# spi1_secure register map
Vendor: Texas Instruments
Peripheral module from a debugger description file (folder CC35X1E).
Registers are 32-bit, access per field, reset 0x0 unless marked. A register's access mark holds for its fields unless they carry their own. Offsets are as the file gives them; lines under a group give offsets from that group; [hi:lo] are bit positions; {n}, {i} and the like mark numbered series; 'fields as' and 'values as' point back to an identical list; <NAME> marks a mode.

## spi1_secure
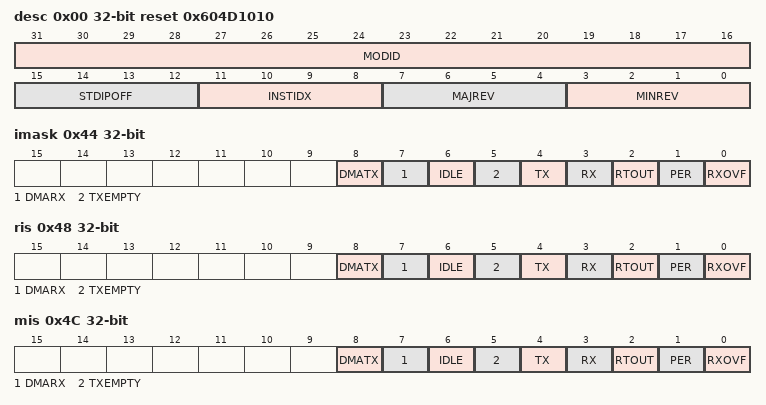
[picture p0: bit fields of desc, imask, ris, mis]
0x00 desc ro reset 0x604D1010 — Description Register. This register provides IP module ID, revision information, instance index and standard MMR registers offset.
  [31:16] MODID — Module identifier used to uniquely identify this IP.
  [15:12] STDIPOFF — Standard IP MMR block offset. Standard IP MMRs are the set of from aggregated IRQ registers till DTB. 0: Standard IP MMRs do not exist 0x1-0xF: Standard IP MMRs begin at offset of (64*[STDIPOFF] from the base IP address)
  [11:8] INSTIDX — IP Instance ID number. If multiple instances of IP exist in the device, this field can identify the instance number (0-15).
  [7:4] MAJREV — Major revision of IP (0-15).
  [3:0] MINREV — Minor revision of IP (0-15).
0x44 imask — Interrupt mask. This register selects interrupt sources which are allowed to pass from [RIS.*] to [MIS.*] when the corresponding bit-fields are set to 1.
  [8] DMATX rw — DMA Done TX event mask.
    1=SET (Set Interrrupt Mask); 0=CLR (Clear Interrupt Mask)
  [7] DMARX rw — DMA Done RX event mask.
    1=SET (Set Interrrupt Mask); 0=CLR (Clear Interrupt Mask)
  [6] IDLE rw — SPI Idle event mask.
    1=SET (Set Interrrupt Mask); 0=CLR (Clear Interrupt Mask)
  [5] TXEMPTY rw — Transmit FIFO Empty event mask.
    1=SET (Set Interrrupt Mask); 0=CLR (Clear Interrupt Mask)
  [4] TX rw — Transmit FIFO event mask.
    1=SET (Set Interrrupt Mask); 0=CLR (Clear Interrupt Mask)
  [3] RX rw — Receive FIFO event.
    1=SET (Set Interrupt Mask); 0=CLR (Clear Interrupt Mask)
  [2] RTOUT rw — SPI Receive Time-Out event mask.
    1=SET (Set Interrrupt Mask); 0=CLR (Clear Interrupt Mask)
  [1] PER rw — Parity error event mask.
    1=SET (Set Interrrupt Mask); 0=CLR (Clear Interrupt Mask)
  [0] RXOVF rw — RXFIFO overflow event mask.
    1=SET (Set Interrrupt Mask); 0=CLR (Clear Interrupt Mask)
0x48 ris ro — Raw interrupt status. This register reflects the state of all pending interrupts, regardless of masking. This register allows the user to implement a poll scheme. A flag set in this register can be cleared by writing 1 to the corresponding [ICLR.*] register bit.
  [all] fields
    1=SET (Interrupt occurred); 0=CLR (Interrupt did not occur)
  [8] DMATX — DMA Done event for TX. This interrupt is set if the TX DMA channel sends the DONE signal. This allows the handling of the TX DMA event inside SPI.
  [7] DMARX — DMA Done event for RX. This interrupt is set if the RX DMA channel sends the DONE signal. This allows handling of the DMA RX event inside SPI.
  [6] IDLE — SPI has completed transfers and moved to IDLE mode. This bit is set when [STA.BUSY] goes low.
  [5] TXEMPTY — Transmit FIFO Empty interrupt mask. This interrupt is set when all data in the Transmit FIFO has been moved to the shift register.
  [4] TX — Transmit FIFO event.This interrupt is set if the selected Transmit FIFO level has been reached.
  [3] RX — Receive FIFO event.This interrupt is set if the selected Receive FIFO level has been reached
  [2] RTOUT — SPI Receive Time-Out event. This interrupt is set if no activity is detected on the input clock line within the time period dictated by [CTL1.RTOUT] value. This is applicable only in peripheral mode.
  [1] PER — Parity error event. This bit is set if a Parity error has been detected
  [0] RXOVF — RXFIFO overflow event. This interrupt is set if an RX FIFO overflow has been detected.
0x4C mis ro — Masked interrupt status. This register is simply a bitwise AND of the contents of [IMASK.*] and [RIS.*] registers. A flag set in this register can be cleared by writing 1 to the corresponding [ICLR.*] register bit.
  [all] fields
    1=SET (Interrupt occurred); 0=CLR (Interrupt did not occur)
  [8] DMATX — Masked DMA Done event for TX.
  [7] DMARX — Masked DMA Done event for RX.
  [6] IDLE — Masked SPI IDLE event.
  [5] TXEMPTY — Masked Transmit FIFO Empty event.
  [4] TX — Masked Transmit FIFO event.
  [3] RX — Masked receive FIFO event.
  [2] RTOUT — Masked SPI Receive Time-Out event.
  [1] PER — Masked Parity error event.
  [0] RXOVF — Masked RXFIFO overflow event.
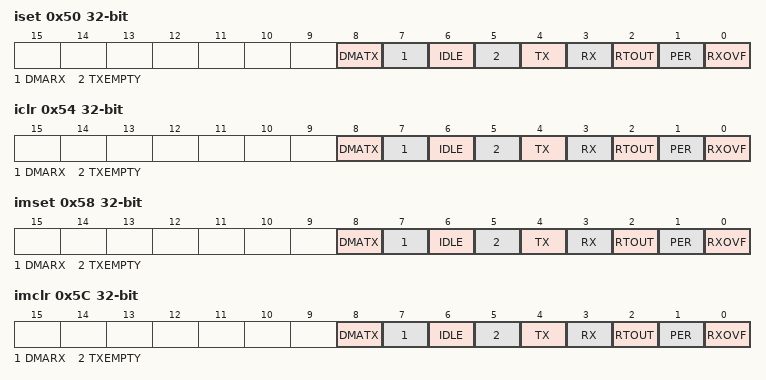
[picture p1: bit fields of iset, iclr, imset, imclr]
0x50 iset — Interrupt set register. This register can used by software for diagnostics and safety checking purposes. Writing a 1 to a bit in this register will set the event and the corresponding [RIS.*] bit also gets set. If the corresponding [IMASK.*] bit is set, then the corresponding [MIS.*] register bit also gets set.
  [8] DMATX wo — Set DMA Done event for TX.
    1=SET (Set Interrupt); 0=NOEFF (Writing 0 has no effect)
  [7] DMARX wo — Set DMA Done event for RX.
    1=SET (Set Interrupt); 0=NOEFF (Writing 0 has no effect)
  [6] IDLE wo — Set SPI IDLE event.
    1=SET (Set Interrupt); 0=NOEFF (Writing 0 has no effect)
  [5] TXEMPTY wo — Set Transmit FIFO Empty event.
    1=SET (Set Interrupt); 0=NOEFF (Writing 0 has no effect)
  [4] TX wo — Set Transmit FIFO event.
    1=SET (Set Interrupt); 0=NOEFF (Writing 0 has no effect)
  [3] RX wo — Set Receive FIFO event.
    1=SET (Set Interrupt); 0=NOEFF (Writing 0 has no effect)
  [2] RTOUT wo — Set SPI Receive Time-Out Event.
    1=SET (Set Interrrupt Mask); 0=NOEFF (Writing 0 has no effect)
  [1] PER wo — Set Parity error event.
    1=SET (Set Interrupt); 0=NOEFF (Writing 0 has no effect)
  [0] RXOVF wo — Set RXFIFO overflow event.
    1=SET (Set Interrupt); 0=NOEFF (Writing 0 has no effect)
0x54 iclr — Interrupt clear register. This register allows software to clear interrupts. Writing a 1 to a bit in this register will clear the event and the corresponding [RIS.*] bit also gets cleared. If the corresponding [IMASK.*] bit is set, then the corresponding [MIS.*] register bit also gets cleared.
  [8] DMATX wo — Clear DMA Done event for TX.
    1=CLR (Clear Interrupt); 0=NOEFF (Writing 0 has no effect)
  [7] DMARX wo — Clear DMA Done event for RX.
    1=CLR (Clear Interrupt); 0=NOEFF (Writing 0 has no effect)
  [6] IDLE wo — Clear SPI IDLE event.
    1=CLR (Clear Interrupt); 0=NOEFF (Writing 0 has no effect)
  [5] TXEMPTY wo — Clear Transmit FIFO Empty event.
    1=CLR (Clear Interrupt); 0=NOEFF (Writing 0 has no effect)
  [4] TX wo — Clear Transmit FIFO event.
    1=CLR (Clear Interrupt); 0=NOEFF (Writing 0 has no effect)
  [3] RX wo — Clear Receive FIFO event.
    1=CLR (Clear Interrupt); 0=NOEFF (Writing 0 has no effect)
  [2] RTOUT wo — Clear SPI Receive Time-Out Event.
    1=CLR (Set Interrrupt Mask); 0=NOEFF (Writing 0 has no effect)
  [1] PER wo — Clear Parity error event.
    1=CLR (Clear Interrupt); 0=NOEFF (Writing 0 has no effect)
  [0] RXOVF wo — Clear RXFIFO overflow event.
    1=CLR (Clear Interrupt); 0=NOEFF (Writing 0 has no effect)
0x58 imset — Interrupt mask set register. Writing a 1 to a bit in this register will set the corresponding [IMASK.*] bit.
  [all] fields
    1=SET (Set interrupt mask); 0=NOEFF (Writing 0 has no effect)
  [8] DMATX wo — Set DMA Done for TX event mask
  [7] DMARX wo — Set DMA Done for RX event mask
  [6] IDLE wo — Set SPI IDLE event mask
  [5] TXEMPTY wo — Set Transmit FIFO Empty event mask
  [4] TX wo — Set Transmit FIFO event mask
  [3] RX wo — Set Receive FIFO event mask
  [2] RTOUT wo — Set SPI Receive Time-Out event mask
  [1] PER wo — Set Parity error event mask
  [0] RXOVF wo — Set RXFIFO overflow event mask
0x5C imclr — Interrupt mask clear register. Writing a 1 to a bit in this register will clear the corresponding [IMASK.*] bit.
  [all] fields
    1=CLR (Clear interrupt mask); 0=NOEFF (Writing 0 has no effect)
  [8] DMATX wo — Clear DMA Done for TX event mask
  [7] DMARX wo — Clear DMA Done for RX event mask
  [6] IDLE wo — Clear SPI IDLE event mask
  [5] TXEMPTY wo — Clear Transmit FIFO Empty event mask
  [4] TX wo — Clear Transmit FIFO event mask
  [3] RX wo — Clear Receive FIFO event mask
  [2] RTOUT wo — Clear SPI Receive Time-Out event mask
  [1] PER wo — Clear Parity error event mask
  [0] RXOVF wo — Clear RXFIFO overflow event mask
0x60 emu — Emulation control register. This register controls the behavior of the IP related to core halted input.
  [0] HALT rw — Halt control
    1=STOP (Freeze option. The IP freezes functionality when the core halted input is asserted, and resumes when it is deasserted. The freeze can either be immediate or after the IP has reached a boundary (end of word boundary, based on DSS configuration) from where it can resume without corruption.); 0=RUN (Free run option. The IP ignores the state of the core halted input.)
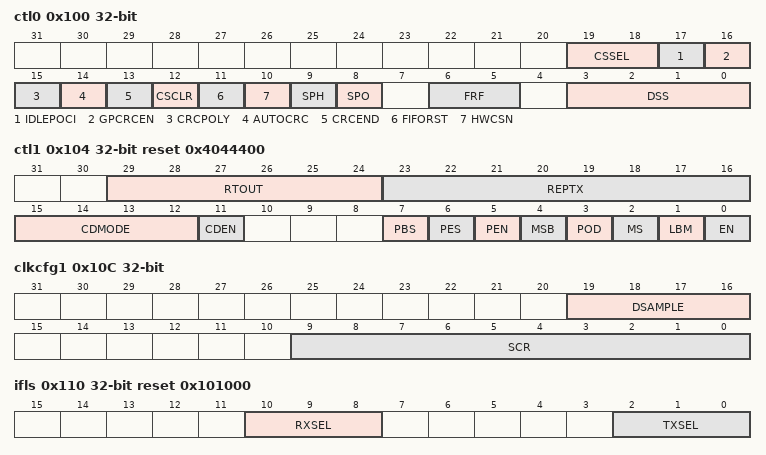
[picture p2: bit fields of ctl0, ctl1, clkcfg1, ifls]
0x100 ctl0 — SPI control register 0
  [19:18] CSSEL rw — CS select for Multi SPI support 00 - CS0 01 - CS1 10 - CS2 11 - CS3
    0=CS0 (Select CS0); 1=CS1 (Select CS1); 2=cs2 (Select CS2); 3=CS3 (Select CS3)
  [17] IDLEPOCI rw — The Idle value of POCI - when TXFIFO is empty and before data is written into TXFIFO - can be controlled by this field.
    0=IDLE_ZERO (POCI output idle value of '0'); 1=IDLE_ONE (POCI outputs idle value of '1')
  [16] GPCRCEN rw — General purpose CRC enable. This bit enables transmit side CRC unit for general purpose use by software when SPI is disabled ([CTL1.EN] = 0). This bit must be 0 when SPI is enabled.
    0=DIS (Transmit side CRC unit is not available for general purpose software use); 1=EN (Transmit side CRC unit is available for general purpose software use)
  [15] CRCPOLY rw — CRC polynomial selection.
    0=_8BIT (Selects 8-bit CCITT CRC polynomial); 1=_16BIT (Selects 16-bit CCITT CRC polynomial)
  [14] AUTOCRC rw — Auto insert CRC
    0=DIS (Do not insert CRC into TXFIFO upon TXFIFO underflow); 1=EN (Insert CRC into TXFIFO upon TXFIFO underflow)
  [13] CRCEND rw — CRC16 Endianness
    0=CRC_END_MSB (Auto-insertion of CRC16 is most-significant byte first); 1=CRC_END_LSB (Auto-insertion of CRC16 is least-significant byte first)
  [12] CSCLR rw — Clear shift register counter on CS inactive. This bit is relevant only in the peripheral mode, when [CTL1.MS]=0.
    0=DIS (Disable automatic clear of shift register when CS goes inactive.); 1=EN (Enable automatic clear of shift register when CS goes inactive.)
  [11] FIFORST rw — This bit is used to reset transmit and receive FIFO pointers. This bit is auto cleared once the FIFO pointer reset operation is completed.
    0=RST_DONE (FIFO pointers reset completed when 0 is read); 1=RST_TRIG (Trigger FIFO pointers reset when written to 1.)
  [10] HWCSN rw — Hardware controlled chip select (CS) value. When set CS is zero till TX FIFO is empty, as in - a. CS is de-asserted b. All data bytes are transmitted c. CS is asserted
    1=EN (HWCS Enable); 0=DIS (HWCS Disable)
  [9] SPH rw — CLKOUT phase (Motorola SPI frame format only). This bit selects the clock edge that captures data and enables it to change state. It has the most impact on the first bit transmitted by either permitting or not permitting a clock transition before the first data capture clock edge.
    0=FIRST (Data is captured on the first clock edge transition.); 1=SECOND (Data is captured on the second clock edge transition.)
  [8] SPO rw — CLKOUT polarity (Motorola SPI frame format only).
    0=LO (SPI produces a steady state LOW value on the CLKOUT); 1=HI (SPI produces a steady state HIGH value on the CLKOUT)
  [6:5] FRF rw — Frame format select
    0=MOTOROLA_3WIRE (Motorola SPI frame format (3 wire mode)); 1=MOTOROLA_4WIRE (Motorola SPI frame format (4 wire mode)); 2=TI_SYNC (TI synchronous serial frame format); 3=MICROWIRE (National Microwire frame format)
  [3:0] DSS rw — Data size select. The applicable DSS values for controller mode operation are 0x3 to 0xF and for peripheral mode operation are 0x6 to 0xF. DSS values 0x0 to 0x2 are reserved and must not be used.
    {v}=BITS_{v+1} ({v+1}-bits data size) (v=3..15)
0x104 ctl1 reset 0x4044400 (reset mask 0x3FFFF700) — SPI control register 1
  [29:24] RTOUT rw — Receive Timeout (only for Peripheral mode) Defines the number of Clock Cycles before after which the Receive Timeout flag [RIS.RTOUT] is set. The time is calculated using the control register for the clock selection and divider in the Controller mode configuration. A value of 0 disables this function.
  [23:16] REPTX rw — Counter to repeat last transfer 0: repeat last transfer is disabled. x: repeat the last transfer with the provided value. The transfer will be started with writing a data into the TX FIFO. Sending the data will be repeated provided value number of times, so the data will be transferred x+1 times in total. The behavior would be as if the data were be written into the TX FIFO as many times as defined by the value here additionally. It can be used to clean a transfer or to pull a certain amount of data by a peripheral.
    0=DIS (REPTX disable)
  [15:12] CDMODE rw — Command Data Mode. This bit field value determines the behavior of C/D or CS signal when [CDEN] = 1. CS pin held low indicates command phase and CS pin held high indicates data phase. When [CDMODE] = 0x0, the CS pin is always held high during transfer indicating data phase only operation (manual mode). When [CDMODE] = 0xF, the CS pin is always held low during transfer indicating command phase only operation (manual mode). When [CDMODE] = 0x1 to 0xE, the CS pin is held low for the number of bytes indicated by [CDMODE] value for the command phase and held high for the remaining transfers in the data phase (automatic mode). When [CDMODE] is set to value 0x1 to 0xE, reading [CDMODE] during operation indicates the remaining bytes to be transferred in the command phase.
    15=COMMAND (Manual mode: Command); 0=DATA (Manual mode: Data)
  [11] CDEN rw — Command/Data mode enable. This feature is applicable only in controller mode and for 8-bit transfers ([CTL0.DSS] = 7). The chip select pin is used for command/data signaling in Motorola SPI frame format (3-wire) operation.
    0=DIS (C/D Mode Disable); 1=EN (C/D Mode Enable)
  [7] PBS rw — Parity bit select
    0=BIT0 (Bit 0 is used for Parity); 1=BIT1 (Bit 1 is used for Parity, Bit 0 is ignored)
  [6] PES rw — Even parity select.
    0=ODD (Odd Parity mode); 1=EVEN (Even Parity mode)
  [5] PEN rw — Parity enable. If enabled the last bit will be used as parity to evaluate the correct reception of the previous bits. In case of parity mismatch the parity error flag [RIS.PER] will be set. This feature is available only in SPI controller mode.
    0=DIS (Disable Parity function); 1=EN (Enable Parity function)
  [4] MSB rw — MSB first select. Controls the direction of receive and transmit shift register. MSB first configuration (MSB = 1) must be selected when CRC feature is used for SPI communication.
    0=LSB (LSB first); 1=MSB (MSB first)
  [3] POD rw — Peripheral data output disable. This bit is relevant only in the peripheral mode, [MS]=1. In multiple-peripheral systems, it is possible for a SPI controller to broadcast a message to all peripherals in the system while ensuring that only one peripheral drives data onto its serial output line. In such systems the POCI lines from multiple peripherals could be tied together. To operate in such systems, this bit field can be set if the SPI peripheral is not supposed to drive the POCI output.
    0=DIS (SPI can drive the POCI output in peripheral mode.); 1=EN (SPI cannot drive the POCI output in peripheral mode.)
  [2] MS rw — Controller or peripheral mode select. This bit can be modified only when SPI is disabled, [CTL1.EN]=0.
    0=PERIPHERAL (Select Peripheral mode); 1=CONTROLLER (Select Controller mode)
  [1] LBM rw — Loop back mode control
    0=DIS (Disable loopback mode. Normal serial port operation enabled.); 1=EN (Enable loopback mode. Output of transmit serial shifter is connected to input of receive serial shifter internally.)
  [0] EN rw — SPI enable.
    0=DIS (SPI is disabled); 1=EN (SPI Enabled and released for operation.)
0x108 clkcfg0 — Clock configuration register 0. This register is used to configure the clock prescaler.
  [2:0] PRESC rw — Prescaler configuration
    0=DIV_BY_1 (Do not divide clock source); {v}=DIV_BY_{v+1} (Divide clock source by {v+1}) (v=1..7)
0x10C clkcfg1 — Clock configuration register 1. This register is used to configure serial clock rate and clock count for delayed sampling in controller mode.
  [19:16] DSAMPLE rw — Delayed sampling. In controller mode the data on the input pin will be delayed sampled by the defined clock cycles. DSAMPLE values can range from 0 to SCR+1. Typically, values of 1 or 2 would suffice.
  [9:0] SCR rw — Serial clock divider. This is used to generate the transmit and receive bit rate of the SPI. The SPI bit rate: (SPI functional clock frequency)/((SCR+1)*2). SCR value can be from 0 to 1023.
0x110 ifls reset 0x101000 (reset mask 0xFFFFF800) — Interrupt FIFO level select register. This register can be used to define the levels at which the [RIS.TX], [RIS.RX] flags are triggered. The interrupts are generated based on FIFO level. Out of reset, the [IFLS.TXSEL] and [IFLS.RXSEL] bits are configured so that the FIFOs trigger an interrupt at the half-way mark.
  [10:8] RXSEL rw — Receive FIFO Level Select. The trigger points for the receive interrupt are as follows:
    0=LVL_OFF (Reserved); 1=LVL_1_4 (RX FIFO >= 1/4 full); 2=LVL_1_2 (RX FIFO >= 1/2 full (default)); 3=LVL_3_4 (RX FIFO >= 3/4 full); 4=LVL_RES4 (Reserved); 5=LVL_FULL (RX FIFO is full); 6=LVL_RES6 (Reserved); 7=LEVEL_1 (Trigger when RX FIFO contains >= 1 byte)
  [2:0] TXSEL rw — Transmit FIFO Level Select. The trigger points for the transmit interrupt are as follows:
    0=LVL_OFF (Reserved); 1=LVL_3_4 (TX FIFO <= 3/4 empty); 2=LVL_1_2 (TX FIFO <= 1/2 empty (default)); 3=LVL_1_4 (TX FIFO <= 1/4 empty); 4=LVL_RES4 (Reserved); 5=LVL_EMPTY (TX FIFO is empty); 6=LVL_RES6 (Reserved); 7=LEVEL_1 (Trigger when TX FIFO has >= 1 byte free)
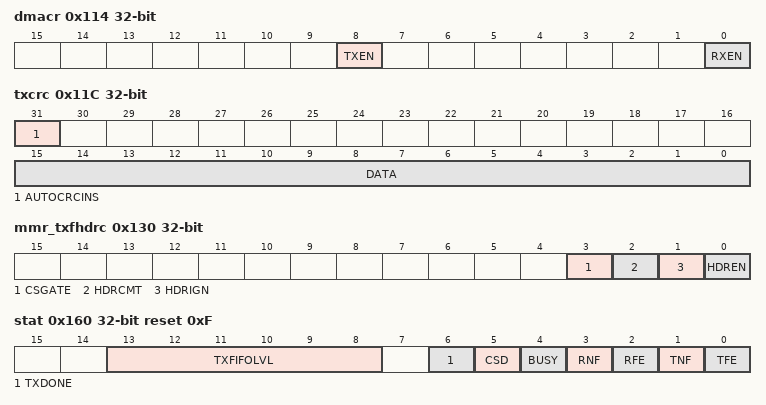
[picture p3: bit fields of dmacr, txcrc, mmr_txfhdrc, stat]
0x114 dmacr — DMA Control Register
  [8] TXEN rw — Transmit DMA enable. If this bit is set to 1, DMA for the transmit FIFO is enabled.
    0=DIS (Disable TX DMA); 1=EN (Enable TX DMA)
  [0] RXEN rw — Receive DMA enable. If this bit is set to 1, DMA for the receive FIFO is enabled.
    0=DIS (Disable RX DMA); 1=EN (Enable RX DMA)
0x118 rxcrc — Receive CRC register. Reading this register provides the computed CRC value from the receive side CRC unit. Reading this register or writing to this register with any value auto initializes the seed. The seed value is 0xFF when [CTL0.CRCPOLY] = 0 and 0xFFFF when [CTL0.CRCPOLY] = 1 for CCITT CRC polynomials. Bits[15:8] are a don't care when [CTL0.CRCPOLY] = 0.
  [15:0] DATA rw — CRC value
0x11C txcrc — Transmit CRC register. Reading this register provides the computed CRC value from the transmit side CRC unit. Reading this register or writing to this register with any value auto initializes the seed. The seed value is 0xFF when [CTL0.CRCPOLY] = 0 and 0xFFFF when [CTL0.CRCPOLY] = 1 for CCITT CRC polynomials. Bits[15:8] are a don't care when [CTL0.CRCPOLY] = 0.
  [31] AUTOCRCINS ro — Status to indicate if Auto CRC has been inserted into TXFIFO. This is applicable only if [CTL0.AUTOCRC] enable bit is set
    0=NOTINS (Auto CRC not yet inserted); 1=INS (Auto CRC inserted)
  [15:0] DATA rw — CRC value
0x120 mmr_txfhdr32 wo — Header update reigster for 32 bits of header data.
  [31:0] DATA — This field can be used to write four bytes of header data
0x124 mmr_txfhdr24 wo — Header update reigster for 24 bits of header data.
  [31:0] DATA — This field can be used to write three bytes of header data
0x128 mmr_txfhdr16 wo — Header update reigster for 16 bits of data.
  [31:0] DATA — This field can be used to write two bytes of header data
0x12C mmr_txfhdr8 wo — Header update reigster for 8 bits of header data.
  [31:0] DATA — This field can be used to write one byte of header data
0x130 mmr_txfhdrc — Atomic Header control register
  [3] CSGATE rw — Chip Select Gating control register. If this bit is set header update register writes are blocked when chip select (CS) is active low, and [HDRIGN] bit is set. This bit resets to 0.
    1=BLK (Header update register writes are blocked when CS is active (low)); 0=UNBLK (The first header update register write is not blocked based on CS active status (low). If no header update occurred when CS was high (inactive), the first header update is allowed when CS is low (active), and the HDRCMT bit is set. The use case is for the external controller to ensure that the SCLK is not driven during this header update. If the header is already updated when CS is high and inactive, HDRCMT is set immediately when CS drops to active low state, and header writes when CS is low are ignored even if this UNBLK bit is set.)
  [2] HDRCMT rw — Header Committed field. This bit is set when the [HDREN] bit is set and CS is sampled low. This bit remains 0 otherwise. When set, this bit can be written to a value of 0 to clear.
    1=SET (Header update is committed); 0=CLEAR (Header update is not committed)
  [1] HDRIGN rw — Header Ignored field. When [CSGATE] is set to BLK, this bit is set when the last Header update register [TXFHDRn.*] is written when CS is low or [HDRCMT] is already set. When [CSGATE] is set to UNBLK, this bit is set only when the header update register is written when [HDRCMT] is already set. This bit remains 0 otherwise. When set, this bit can be written to a value of 0 to clear.
    1=SET (Header update is ignored); 1=CLEAR (Header update is not ignored)
  [0] HDREN rw — Header enable field. When [CSGATE] is set to BLK, this bit has to be set by software to enable this feature. When [CSGATE] is set to UNBLK, this field is set automatically whenever a write to header update registers occurs [TXFHDRn.*]
    0=DIS (Atomic header update feature disable); 1=EN (Atomic header update feature enable)
0x140 rxdata ro — RXDATA Register. Reading this register returns first value in the RX FIFO. If the FIFO is empty the last read value is returned. Writing has no effect and is ignored.
  [15:0] DATA — Received Data. When read, the entry in the receive FIFO, pointed to by the current FIFO read pointer is accessed. As data values are read by the receive logic from the incoming data frame, they are placed into the entry in the receive FIFO, pointed to by the current RX FIFO write pointer. Received data less than 16 bits is automatically right-justified in the receive buffer.
0x150 txdata — TXDATA Register. Writing a value in this register puts the data into the TX FIFO. Reading this register returns the last written value.
  [15:0] DATA rw — Transmit Data. When read, the last entry in the transmit FIFO, pointed to by the current FIFO write pointer is accessed. When written, the entry in the TX FIFO pointed to by the write pointer, is written to. Data values are read from the transmit FIFO by the transmit logic. It is loaded into the transmit serial shifter, then serially shifted out onto the output pin at the programmed bit rate. When a data size of less than 16 bits is selected, the user must right-justify data written to the transmit FIFO. The transmit logic ignores the unused bits.
0x160 stat reset 0xF — Status Register
  [13:8] TXFIFOLVL ro — Indicates how many locations of TXFIFO are currently filled with data
  [6] TXDONE rw — Transmit done. Indicates whether the last bit left the Shift register after a transmission
    1=TX_DONE (Last bit has been shifted out, and the transmission is done); 0=TX_ONGOING (Last bit has not yet left the Shift register, and the transmission is ongoing.)
  [5] CSD rw — Detection of CS deassertion in the middle of a word transmission results in this error being set. This feature is only available in the peripheral mode.
    1=ERR (An error is generated when CS posedge (deassertion) is detected before the entire word is transmitted.); 0=NOERR (No CS posedge is detected before the entire word has been transmitted.)
  [4] BUSY ro — SPI Busy status
    1=ACTIVE (SPI is currently transmitting and/or receiving data, or transmit FIFO is not empty.); 0=IDLE (SPI is in idle mode.)
  [3] RNF ro — Receive FIFO not full status.
    1=NOT_FULL (Receive FIFO is not full.); 0=FULL (Receive FIFO is full.)
  [2] RFE ro — Receive FIFO empty status.
    0=NOT_EMPTY (Receive FIFO is not empty.); 1=EMPTY (Receive FIFO is empty.)
  [1] TNF ro — Transmit FIFO not full status.
    1=NOT_FULL (Transmit FIFO is not full.); 0=FULL (Transmit FIFO is full.)
  [0] TFE ro — Transmit FIFO empty status.
    0=NOT_EMPTY (Transmit FIFO is not empty.); 1=EMPTY (Transmit FIFO is empty.)
0x1000 clk_en_reg — Clock Enable Register
  [0] ENABLE rw — SPI main clock Enable
